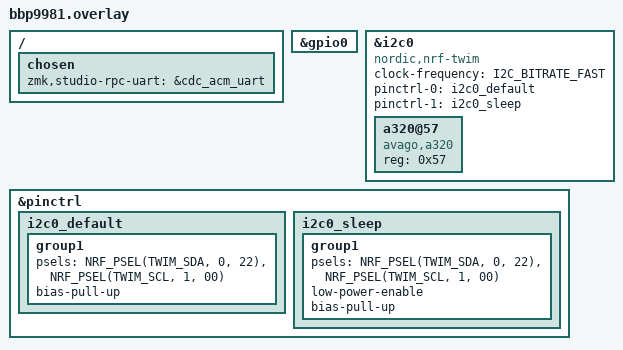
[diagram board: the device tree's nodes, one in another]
/ {
    chosen {
        zmk,studio-rpc-uart = &cdc_acm_uart; // ✅ 这是正确的 UART 设备引用
    };
};

&gpio0 {
    status = "okay";
};

&i2c0 {
    status = "okay";
    compatible = "nordic,nrf-twim";
    clock-frequency = <I2C_BITRATE_FAST>; 
    pinctrl-0 = <&i2c0_default>;
    pinctrl-1 = <&i2c0_sleep>;
    pinctrl-names = "default", "sleep";

    a320@57 {
        compatible = "avago,a320";
        reg = <0x57>;
        status = "okay";
    };
};

&pinctrl {
    i2c0_default: i2c0_default {
        group1 {
            psels = <NRF_PSEL(TWIM_SDA, 0, 22)>,
                    <NRF_PSEL(TWIM_SCL, 1, 00)>;
            bias-pull-up;
        };
    };
    i2c0_sleep: i2c0_sleep {
        group1 {
            psels = <NRF_PSEL(TWIM_SDA, 0, 22)>,
                    <NRF_PSEL(TWIM_SCL, 1, 00)>;
            low-power-enable;
            bias-pull-up;
        };
    };
};
